AUTOSAR XML (schema 4-2-1)
package /ECUCompositionType
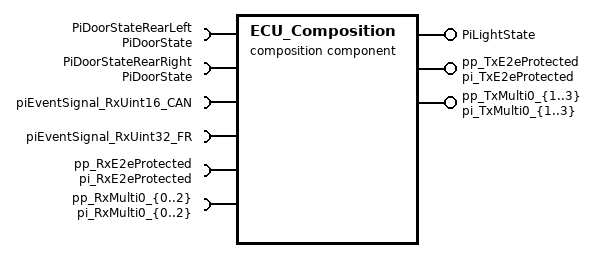
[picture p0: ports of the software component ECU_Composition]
  composition sw component type ECU_Composition
    5 x provide port:
      PiLightState: nonqueued-sender-com-spec{data-element=DeLightState, init-value=0}, provided-interface=PiLightState
      pp_TxE2eProtected: nonqueued-sender-com-spec{data-element=sgTx_E2eProt, uses-end-to-end-protection=true, init-value=fields=[ElementConstant:0, ElementConstant_1:0, ElementConstant_2:0, ElementConstant_3:0, ElementConstant_4:0, ElementConstant_5:0, ElementConstant_6:0]}, provided-interface=pi_TxE2eProtected
      pp_TxMulti0_{1..3}: nonqueued-sender-com-spec=data-element=deTxMulti0_{1..3}, provided-interface=pi_TxMulti0_{1..3}
    8 x require port:
      PiDoorStateRearLeft: nonqueued-receiver-com-spec{data-element=DeDoorState, filter=data-filter-type=ALWAYS, init-value=0}, required-interface=PiDoorState
      PiDoorStateRearRight: nonqueued-receiver-com-spec{data-element=DeDoorState, filter=data-filter-type=ALWAYS, init-value=0}, required-interface=PiDoorState
      piEventSignal_RxUint16_CAN: nonqueued-receiver-com-spec{data-element=deEventSignal_RxUint16_CAN, filter=data-filter-type=ALWAYS, init-value=25}, required-interface=piEventSignal_RxUint16_CAN
      piEventSignal_RxUint32_FR: nonqueued-receiver-com-spec{data-element=deEventSignal_RxUint32_FR, filter=data-filter-type=ALWAYS, init-value=1}, required-interface=piEventSignal_RxUint32_FR
      pp_RxE2eProtected: nonqueued-receiver-com-spec{data-element=sgRx_E2eProt, uses-end-to-end-protection=true, enable-update=true, filter=data-filter-type=ALWAYS, init-value=fields=[ElementConstant:0, ElementConstant_1:0, ElementConstant_2:0, ElementConstant_3:0, ElementConstant_4:0, ElementConstant_5:0]}, required-interface=pi_RxE2eProtected
      pp_RxMulti0_{0..2}: nonqueued-receiver-com-spec{data-element=deRxMulti0_{0..2}, filter=data-filter-type=ALWAYS, init-value=0}, required-interface=pi_RxMulti0_{0..2}
    6 x component:
      CpCoApplication: type=CtCoApplication
      CtCryptoDemo: type=CtCryptoDemo
      CtDiagDemo: type=CtDiagDemo
      CtDltDemo: type=CtDltDemo
      CtE2eCommunication: type=CtE2eCommunication
      CtFimDemo: type=CtFimDemo
    connect CtDiagDemo.DiagDemo_ResetConfirmation -> CpCoApplication.ApMySwc_ResetConfirmation
    delegate CpCoApplication.PpDoorStateRearLeft <-> outer port PiDoorStateRearLeft
    delegate CpCoApplication.PpDoorStateRearRight <-> outer port PiDoorStateRearRight
    delegate CtDltDemo.piEventSignal_RxUint16_CAN <-> outer port piEventSignal_RxUint16_CAN
    delegate CtDltDemo.piEventSignal_RxUint32_FR <-> outer port piEventSignal_RxUint32_FR
    delegate CpCoApplication.PpLightStateRear <-> outer port PiLightState
    delegate CtE2eCommunication.pp_RxE2eProtected <-> outer port pp_RxE2eProtected
    delegate CtCryptoDemo.pp_RxMulti0_{0..2} <-> outer port pp_RxMulti0_{0..2}
    delegate CtE2eCommunication.pp_TxE2eProtected <-> outer port pp_TxE2eProtected
    delegate CtCryptoDemo.pp_TxMulti0_{1..3} <-> outer port pp_TxMulti0_{1..3}
package /EndToEndProtection
  end to end protection set EndToEndConnections
    end to end protection Ext_ECU_Composition_pp_RxE2eProtected_sgRx_E2eProt: end-to-end-profile={category=PROFILE_01, data-ids=1, data-id-mode=3, data-length=56, max-delta-counter-init=0, crc-offset=0, counter-offset=8, data-id-nibble-offset=12}, end-to-end-protection-variable-prototype=receiver=CtE2eCommunication.ECU_Composition.pp_RxE2eProtected.sgRx_E2eProt
    end to end protection Ext_ECU_Composition_pp_TxE2eProtected_sgTx_E2eProt: end-to-end-profile={category=PROFILE_01, data-ids=1, data-id-mode=3, data-length=56, max-delta-counter-init=0, crc-offset=0, counter-offset=8, data-id-nibble-offset=12}, end-to-end-protection-variable-prototype=CtE2eCommunication.ECU_Composition.pp_TxE2eProtected.sgTx_E2eProt
package /VehicleProject
  system System: category=SYSTEM_EXTRACT
    system mapping System_MPPNG
      data-mappings:
        sender-receiver-to-signal-group-mapping={data-element=ECU_Composition.pp_TxE2eProtected.sgTx_E2eProt, signal-group=SG_SgTx_Prof1C_TxCycle, type-mapping=sender-rec-record-type-mapping=record-element-mappings=[{implementation-record-element=reTx_E2eProt_SQ, system-signal=SigTx_Prof1C_SQ}, {implementation-record-element=reTx_E2eProt_DataId, system-signal=SigTx_Prof1C_DataId_HiByte_LoNib}, {implementation-record-element=reTx_E2eProt_CRC, system-signal=SigTx_Prof1C_CRC}, {implementation-record-element=reTx_E2eProt_8Bit, system-signal=SigTx_Prof1C_Sig8Bit}, {implementation-record-element=reTx_E2eProt_4Bit, system-signal=SigTx_Prof1C_Sig4Bit}, {implementation-record-element=reTx_E2eProt_2Bit, system-signal=SigTx_Prof1C_Sig2Bit}, {implementation-record-element=reTx_E2eProt_16Bit, system-signal=SigTx_Prof1C_Sig16Bit}]}
        sender-receiver-to-signal-mapping={data-element=ECU_Composition.PiDoorStateRearLeft.DeDoorState, system-signal=Signal_RearLeftDoor}
        sender-receiver-to-signal-mapping={data-element=ECU_Composition.PiDoorStateRearRight.DeDoorState, system-signal=Signal_RearRightDoor}
        sender-receiver-to-signal-group-mapping={data-element=ECU_Composition.pp_RxE2eProtected.sgRx_E2eProt, signal-group=SG_RgRx_Prof1C_RxCycle, type-mapping=sender-rec-record-type-mapping=record-element-mappings=[{implementation-record-element=reRx_E2eProt_SQ, system-signal=SigRx_Prof1C_SQ}, {implementation-record-element=reRx_E2eProt_DataId, system-signal=SigRx_Prof1C_DataId_HiByte_LoNib}, {implementation-record-element=reRx_E2eProt_CRC, system-signal=SigRx_Prof1C_CRC}, {implementation-record-element=reRx_E2eProt_4Bit, system-signal=SigRx_Prof1C_Sig4Bit}, {implementation-record-element=reRx_E2eProt_3Bit, system-signal=SigRx_Prof1C_Sig3Bit}, {implementation-record-element=reRx_E2eProt_32Bit, system-signal=SigRx_Prof1C_Sig32Bit}]}
        sender-receiver-to-signal-mapping={data-element=ECU_Composition.PiLightState.DeLightState, system-signal=Signal_SwitchRearInteriorLight}
    root-software-compositions:
      root sw composition prototype ECU_Composition: software-composition=ECU_Composition
